# STM32H7B0xxQ register map
File version: 1.0
Registers are 32-bit, read-write, reset 0x0 unless marked. A register's access mark holds for its fields unless they carry their own. Offsets are from the block's base; [hi:lo] are bit positions; {n}, {i} and the like mark numbered series.

## DCMI
Base 0x48020000
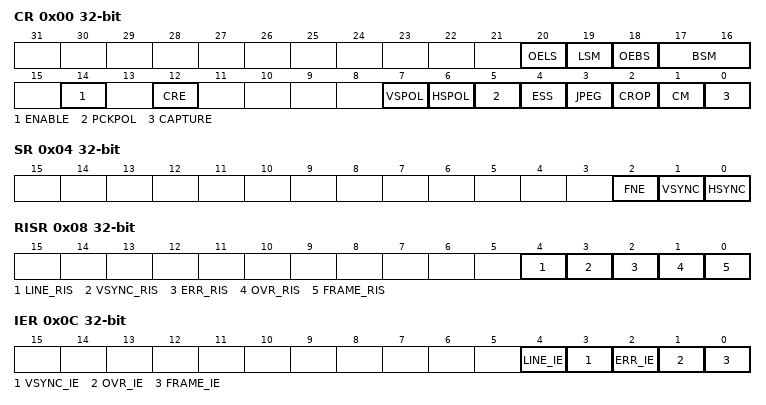
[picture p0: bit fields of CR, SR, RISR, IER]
0x00 CR — DCMI control register 1
  [20] OELS, [19] LSM, [18] OEBS, [17:16] BSM, [14] ENABLE, [12] CRE, [7] VSPOL, [6] HSPOL, [5] PCKPOL, [4] ESS, [3] JPEG, [2] CROP, [1] CM, [0] CAPTURE
0x04 SR — DCMI status register
  [2] FNE, [1] VSYNC, [0] HSYNC
0x08 RISR — DCMI raw interrupt status register
  [4] LINE_RIS, [3] VSYNC_RIS, [2] ERR_RIS, [1] OVR_RIS, [0] FRAME_RIS
0x0C IER — DCMI interrupt enable register
  [4] LINE_IE, [3] VSYNC_IE, [2] ERR_IE, [1] OVR_IE, [0] FRAME_IE
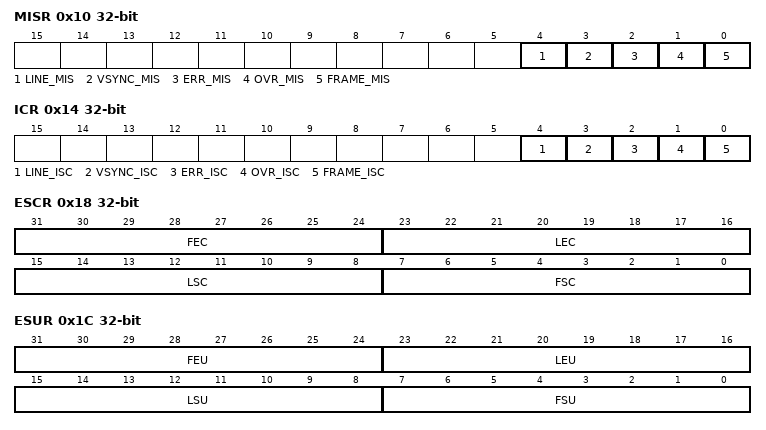
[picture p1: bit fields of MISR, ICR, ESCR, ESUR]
0x10 MISR — DCMI masked interrupt status register
  [4] LINE_MIS, [3] VSYNC_MIS, [2] ERR_MIS, [1] OVR_MIS, [0] FRAME_MIS
0x14 ICR — DCMI interrupt clear register
  [4] LINE_ISC, [3] VSYNC_ISC, [2] ERR_ISC, [1] OVR_ISC, [0] FRAME_ISC
0x18 ESCR — DCMI embedded synchronization code register
  [31:24] FEC, [23:16] LEC, [15:8] LSC, [7:0] FSC
0x1C ESUR — DCMI embedded synchronization unmask register
  [31:24] FEU, [23:16] LEU, [15:8] LSU, [7:0] FSU
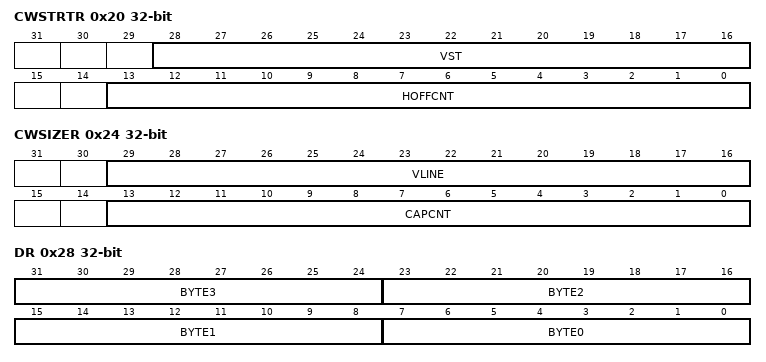
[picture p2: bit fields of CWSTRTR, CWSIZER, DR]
0x20 CWSTRTR — DCMI crop window start
  [28:16] VST, [13:0] HOFFCNT
0x24 CWSIZER — DCMI crop window size
  [29:16] VLINE, [13:0] CAPCNT
0x28 DR — DCMI data register
  [8n+7:8n] BYTE{n} (n=0..3)

## PSSI
Base 0x48020400
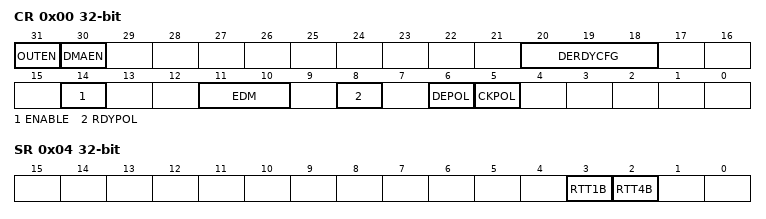
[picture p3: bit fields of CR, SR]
0x00 CR — PSSI control register 1
  [31] OUTEN — Data direction selection
  [30] DMAEN — DMA enable
  [20:18] DERDYCFG — Data enable and ready configuration
  [14] ENABLE — PSSI enable
  [11:10] EDM — Extended data mode
  [8] RDYPOL — Ready polarity
  [6] DEPOL — Data enable polarity
  [5] CKPOL — Parallel data clock polarity
0x04 SR — PSSI status register
  [3] RTT1B — Ready to transfer one byte
  [2] RTT4B — Ready to transfer four bytes
0x08 RIS — PSSI raw interrupt status register
  [1] OVR_RIS — Data buffer overrun/underrun raw interrupt status
0x0C IER — PSSI interrupt enable register
  [1] OVR_IE — Data buffer overrun/underrun interrupt enable
0x10 MIS — PSSI masked interrupt status register
  [1] OVR_MIS — Data buffer overrun/underrun masked interrupt status
0x14 ICR — PSSI interrupt clear register
  [1] OVR_ISC — Data buffer overrun/underrun interrupt status clear
0x28 DR — PSSI data register
  [31:0] DR — Data register
0x3F0 HWCFGR — PSSI IP HW configuration register
0x3F4 VERR — PSSI IP version register
0x3F8 IPIDR — PSSI IP ID register
0x3FC SIDR — PSSI SIZE ID register

## HSEM — HW Semaphore HSEM
Base 0x48020800
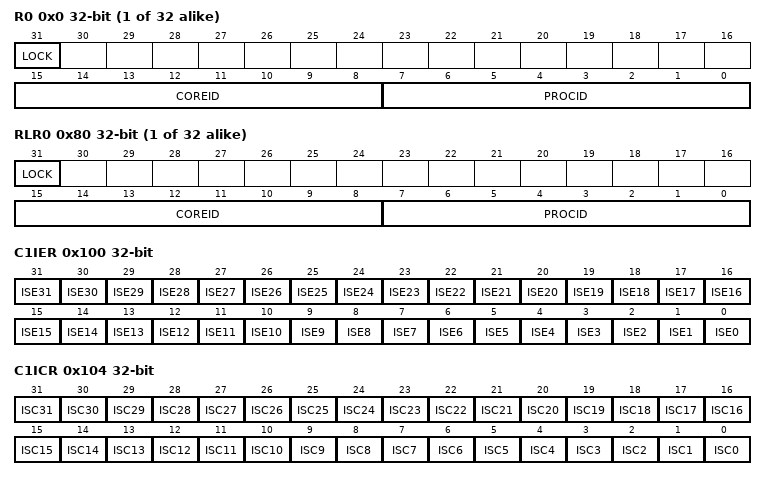
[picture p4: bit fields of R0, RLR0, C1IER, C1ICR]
{0x0+4i} R{i} (i=0..31) — 2-step write lock and read back registers
  [31] LOCK — Lock indication
  [15:8] COREID — Semaphore CoreID
    0=NONE; 1=CPU1
  [7:0] PROCID — Semaphore ProcessID
{0x80+4i} RLR{i} (i=0..31) — 1-step read lock registers
  [31] LOCK — Lock indication
  [15:8] COREID — Semaphore CoreID
  [7:0] PROCID — Semaphore ProcessID
0x100 C1IER — HSEM Interrupt enable register
  [n] ISE{n} (n=5..31) — semaphore {n} interrupt 0 enable bit
  [n] ISE{n} (n=0..4) — semaphore {n} , interrupt 0 enable bit
0x104 C1ICR — HSEM Interrupt clear register
  [n] ISC{n} (n=5..31) — semaphore {n} interrupt 0 clear bit
  [n] ISC{n} (n=0..4) — semaphore {n} , interrupt 0 clear bit
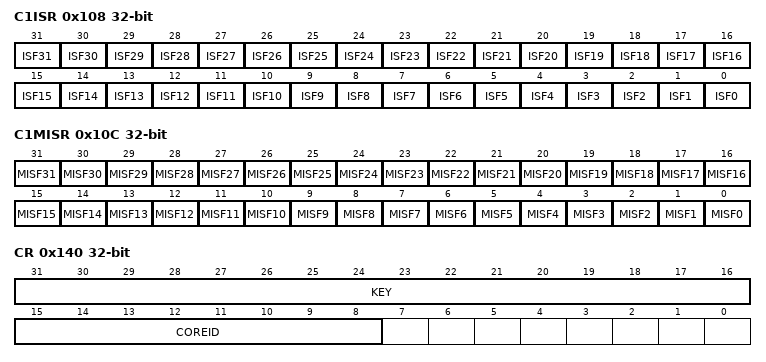
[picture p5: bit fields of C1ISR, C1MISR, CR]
0x108 C1ISR — HSEM Interrupt Status register
  [n] ISF{n} (n=0..31) — semaphore {n} interrupt 0 status bit
0x10C C1MISR — HSEM Interrupt Masked Status register
  [n] MISF{n} (n=0..31) — semaphore {n} interrupt 0 masked status bit
0x140 CR — HSEM Semaphore clear register
  [31:16] KEY — semaphores clear key
  [15:8] COREID — CoreID of semaphores to be cleared
0x144 KEYR — HSEM Semaphore clear key register
  [31:16] KEY — semaphores clear key

## CRYP — Crypto Processor
Base 0x48021000
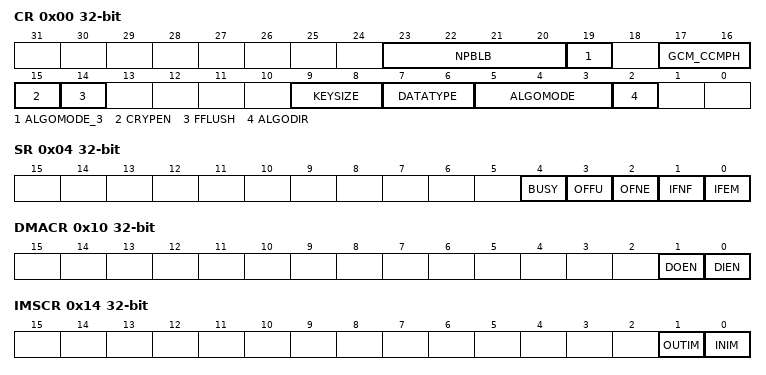
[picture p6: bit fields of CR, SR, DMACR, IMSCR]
0x00 CR — CRYP control register
  [23:20] NPBLB, [19] ALGOMODE_3, [17:16] GCM_CCMPH, [15] CRYPEN, [14] FFLUSH, [9:8] KEYSIZE, [7:6] DATATYPE, [5:3] ALGOMODE, [2] ALGODIR
0x04 SR — CRYP status register
  [4] BUSY, [3] OFFU, [2] OFNE, [1] IFNF, [0] IFEM
0x08 DIN — CRYP data input register
0x0C DOUT — CRYP data output register
0x10 DMACR — CRYP DMA control register
  [1] DOEN, [0] DIEN
0x14 IMSCR — CRYP interrupt mask set/clear register
  [1] OUTIM, [0] INIM
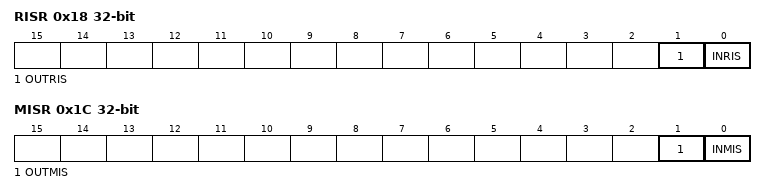
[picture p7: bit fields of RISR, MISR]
0x18 RISR — CRYP raw interrupt status register
  [1] OUTRIS, [0] INRIS
0x1C MISR — CRYP masked interrupt status register
  [1] OUTMIS, [0] INMIS
{0x20+8i} K{i}LR (i=0..3) — CRYP key left register {i}
{0x24+8i} K{i}RR (i=0..3) — CRYP key right register {i}
0x40 IV0LR — CRYP initialization vector left-word register 0
0x44 IV0RR — CRYP initialization vector right-word register 0
0x48 IV1LR — CRYP initialization vector left-word register 1
0x4C IV1RR — CRYP initialization vector right-word register 1
{0x50+4i} CSGCMCCM{i}R (i=0..7) — CRYP GCM/GMAC or CCM/CMAC context swap register {i}
{0x70+4i} CSGCM{i}R (i=0..7) — CRYP GCM/GMAC context swap register {i}
